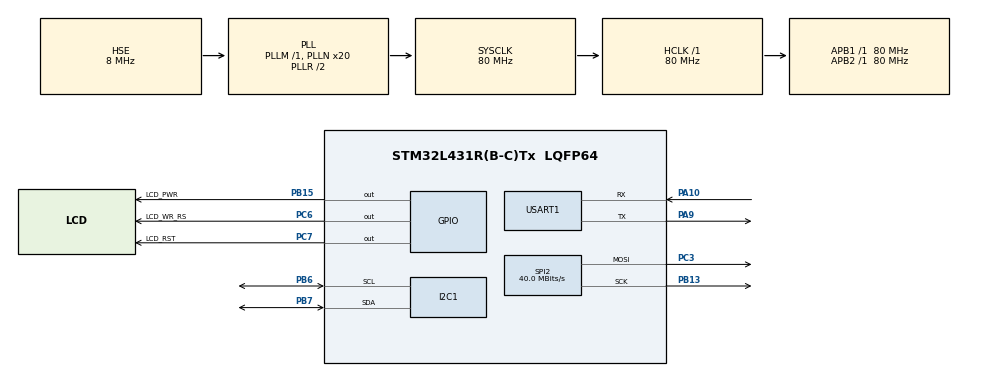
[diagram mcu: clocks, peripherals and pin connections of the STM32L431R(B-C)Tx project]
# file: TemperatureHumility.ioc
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Mcu.Family=STM32L4
Mcu.Name=STM32L431R(B-C)Tx
Mcu.Package=LQFP64
NVIC.PriorityGroup=NVIC_PRIORITYGROUP_4
PA10.Mode=Asynchronous
PA10.Signal=USART1_RX
PA9.Mode=Asynchronous
PA9.Signal=USART1_TX
PB13.Mode=TX_Only_Simplex_Unidirect_Master
PB13.Signal=SPI2_SCK
PB15.GPIO_Label=LCD_PWR
PB15.Signal=GPIO_Output
PB6.Mode=I2C
PB6.Signal=I2C1_SCL
PB7.Mode=I2C
PB7.Signal=I2C1_SDA
PC14-OSC32_IN\ (PC14).Mode=LSE-External-Oscillator
PC14-OSC32_IN\ (PC14).Signal=RCC_OSC32_IN
PC15-OSC32_OUT\ (PC15).Mode=LSE-External-Oscillator
PC15-OSC32_OUT\ (PC15).Signal=RCC_OSC32_OUT
PC3.Mode=TX_Only_Simplex_Unidirect_Master
PC3.Signal=SPI2_MOSI
PC6.GPIO_Label=LCD_WR_RS
PC6.Signal=GPIO_Output
PC7.GPIO_Label=LCD_RST
PC7.Signal=GPIO_Output
PH0-OSC_IN\ (PH0).Mode=HSE-External-Oscillator
PH0-OSC_IN\ (PH0).Signal=RCC_OSC_IN
PH1-OSC_OUT\ (PH1).Mode=HSE-External-Oscillator
PH1-OSC_OUT\ (PH1).Signal=RCC_OSC_OUT
ProjectManager.HeapSize=0x200
ProjectManager.StackSize=0x400
ProjectManager.TargetToolchain=SW4STM32
RCC.ADCFreq_Value=32000000
RCC.AHBFreq_Value=80000000
RCC.APB1Freq_Value=80000000
RCC.APB1TimFreq_Value=80000000
RCC.APB2Freq_Value=80000000
RCC.APB2TimFreq_Value=80000000
RCC.CortexFreq_Value=80000000
RCC.HCLKFreq_Value=80000000
RCC.HSE_VALUE=8000000
RCC.HSI48_VALUE=48000000
RCC.HSI_VALUE=16000000
RCC.MSI_VALUE=4000000
RCC.PLLN=20
RCC.PLLSourceVirtual=RCC_PLLSOURCE_HSE
RCC.SYSCLKFreq_VALUE=80000000
RCC.SYSCLKSource=RCC_SYSCLKSOURCE_PLLCLK
RCC.VCOOutputFreq_Value=160000000
SPI2.CLKPhase=SPI_PHASE_2EDGE
SPI2.CLKPolarity=SPI_POLARITY_HIGH
SPI2.CalculateBaudRate=40.0 MBits/s
SPI2.DataSize=SPI_DATASIZE_8BIT
SPI2.Direction=SPI_DIRECTION_2LINES
SPI2.Mode=SPI_MODE_MASTER
SPI2.VirtualType=VM_MASTER
USART1.VirtualMode-Asynchronous=VM_ASYNC
board=custom

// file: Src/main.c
/* USER CODE BEGIN Header */
/**
  ******************************************************************************
  * @file           : main.c
  * @brief          : Main program body
  ******************************************************************************
  * @attention
  *
  * <h2><center>&copy; Copyright (c) 2020 STMicroelectronics.
  * All rights reserved.</center></h2>
  *
  * This software component is licensed by ST under BSD 3-Clause license,
  * the "License"; You may not use this file except in compliance with the
  * License. You may obtain a copy of the License at:
  *                        opensource.org/licenses/BSD-3-Clause
  *
  ******************************************************************************
  */
/* USER CODE END Header */

#include "main.h"
#include "i2c.h"
#include "spi.h"
#include "usart.h"
#include "gpio.h"
#include "printfRedirection.h"
#include "sht30_i2c_drv.h"
#include <stdlib.h>
#include <lcd_spi2_drv.h>

void PrintFloat(float value)
{
    int tmp,tmp1,tmp2,tmp3,tmp4,tmp5,tmp6;
    tmp = (int)value;
    tmp1=(int)((value-tmp)*10)%10;
    tmp2=(int)((value-tmp)*100)%10;
    tmp3=(int)((value-tmp)*1000)%10;
    tmp4=(int)((value-tmp)*10000)%10;
    tmp5=(int)((value-tmp)*100000)%10;
    tmp6=(int)((value-tmp)*1000000)%10;
    printf("%d.%d%d%d%d%d%d",tmp,tmp1,tmp2,tmp3,tmp4,tmp5,tmp6);
}

void recurParse(int n, char** str, unsigned int* restSize) {
    if (n < 10) {
        if (*restSize > 1) {
            **str = n + '0';
            (*str)++;
            *restSize -= 1;
        }

    }
    else {
        recurParse(n / 10, str, restSize);
        if (*restSize > 1) {
            **str = n % 10 + '0';
            (*str)++;
            *restSize -= 1;
        }
    }
}
/*
*outBuffer: 输出字符串的缓冲区
*bufferSize: 输出字符串缓冲区的大小
*in: 要转换的浮点数
*decCount: 输出字符串保留的小数位数
*返回值: 写入到缓冲区中的字符个数（不包含\0）
*/
int float2String(char* outBuffer, unsigned int bufferSize, float in, unsigned int decCount) {
    int n;
    float dec;
    unsigned int restSize = bufferSize;
    if (restSize == 0) return 0;
    n = (int)in;
    dec = in - n;
    if (in < 0) {
        if (restSize > 1 && !(n == 0 && decCount == 0)) {
            *outBuffer++ = '-';
            --restSize;
        }
        n = -n;
    }
    if (dec < 0) {
        dec = -dec;
    }
    recurParse(n, &outBuffer, &restSize);
    if (decCount != 0) {
        if (restSize > 1) {
            *outBuffer++ = '.';
            --restSize;
        }
    }
    while (decCount) {
        dec *= 10;
        n = (int)dec;
        dec -= n;
        if (restSize > 1) {
            *outBuffer++ = n + '0';
            --restSize;
        }
        else {
            break;
        }
        decCount -= 1;
    }
    *outBuffer++ = NULL;
    return bufferSize - restSize;
}

void SystemClock_Config(void);

int main(void)
{
  /* USER CODE BEGIN 1 */
  uint8_t recv_dat[6] = {0};
  float temperature = 0.0;
  float humidity = 0.0;

    char strValue[8] = {0};

  /* USER CODE END 1 */

  /* MCU Configuration--------------------------------------------------------*/

  /* Reset of all peripherals, Initializes the Flash interface and the Systick. */
  HAL_Init();

  /* Configure the system clock */
  SystemClock_Config();

  /* Initialize all configured peripherals */
  MX_GPIO_Init();
  MX_I2C1_Init();
  MX_SPI2_Init();
  MX_USART1_UART_Init();
  /* USER CODE BEGIN 2 */
  LCD_Init();
  //LCD_Clear(GREEN);
  LCD_Clear(BLACK);

  SHT30_reset();
  if(SHT30_Init() == HAL_OK){
      printf("sht30 init ok.\n");
  }
  else{
      printf("sht30 init fail.\n");
  }

  /* USER CODE END 2 */

  /* Infinite loop */
  while (1)
  {
    HAL_Delay(1000);
    if(SHT30_Read_Dat(recv_dat) == HAL_OK){
        if(SHT30_Dat_To_Float(recv_dat, &temperature, &humidity) == 0) {
            printf("Temperature = ");PrintFloat(temperature);
            printf(", ");
            printf("Humidity = ");PrintFloat(humidity);
            printf("\n");
            LCD_ShowCharStr(0,120-32,180,"Temperature\:",BLACK,RED,24);
            float2String(strValue, sizeof(strValue)/sizeof(char), temperature, 2);
            LCD_ShowCharStr(160,120-32,60,strValue,BLACK,RED,24);

            LCD_ShowCharStr(0,120,180,"Humidity\:",BLACK,RED,24);
            float2String(strValue, sizeof(strValue)/sizeof(char), humidity, 2);
            LCD_ShowCharStr(160,120,60,strValue,BLACK,RED,24);
        }
        else{
            printf("crc check fail.\n");
        }
    }
    else{
        printf("read data from sht30 fail.\n");
    }

  }
}

void SystemClock_Config(void)
{
  RCC_OscInitTypeDef RCC_OscInitStruct = {0};
  RCC_ClkInitTypeDef RCC_ClkInitStruct = {0};
  RCC_PeriphCLKInitTypeDef PeriphClkInit = {0};

  /** Initializes the CPU, AHB and APB busses clocks
  */
  RCC_OscInitStruct.OscillatorType = RCC_OSCILLATORTYPE_HSE;
  RCC_OscInitStruct.HSEState = RCC_HSE_ON;
  RCC_OscInitStruct.PLL.PLLState = RCC_PLL_ON;
  RCC_OscInitStruct.PLL.PLLSource = RCC_PLLSOURCE_HSE;
  RCC_OscInitStruct.PLL.PLLM = 1;
  RCC_OscInitStruct.PLL.PLLN = 20;
  RCC_OscInitStruct.PLL.PLLP = RCC_PLLP_DIV7;
  RCC_OscInitStruct.PLL.PLLQ = RCC_PLLQ_DIV2;
  RCC_OscInitStruct.PLL.PLLR = RCC_PLLR_DIV2;
  if (HAL_RCC_OscConfig(&RCC_OscInitStruct) != HAL_OK)
  {
    Error_Handler();
  }
  /** Initializes the CPU, AHB and APB busses clocks
  */
  RCC_ClkInitStruct.ClockType = RCC_CLOCKTYPE_HCLK|RCC_CLOCKTYPE_SYSCLK
                              |RCC_CLOCKTYPE_PCLK1|RCC_CLOCKTYPE_PCLK2;
  RCC_ClkInitStruct.SYSCLKSource = RCC_SYSCLKSOURCE_PLLCLK;
  RCC_ClkInitStruct.AHBCLKDivider = RCC_SYSCLK_DIV1;
  RCC_ClkInitStruct.APB1CLKDivider = RCC_HCLK_DIV1;
  RCC_ClkInitStruct.APB2CLKDivider = RCC_HCLK_DIV1;

  if (HAL_RCC_ClockConfig(&RCC_ClkInitStruct, FLASH_LATENCY_4) != HAL_OK)
  {
    Error_Handler();
  }
  PeriphClkInit.PeriphClockSelection = RCC_PERIPHCLK_USART1|RCC_PERIPHCLK_I2C1;
  PeriphClkInit.Usart1ClockSelection = RCC_USART1CLKSOURCE_PCLK2;
  PeriphClkInit.I2c1ClockSelection = RCC_I2C1CLKSOURCE_PCLK1;
  if (HAL_RCCEx_PeriphCLKConfig(&PeriphClkInit) != HAL_OK)
  {
    Error_Handler();
  }
  /** Configure the main internal regulator output voltage
  */
  if (HAL_PWREx_ControlVoltageScaling(PWR_REGULATOR_VOLTAGE_SCALE1) != HAL_OK)
  {
    Error_Handler();
  }
}

void Error_Handler(void)
{
}

/************************ (C) COPYRIGHT STMicroelectronics *****END OF FILE****/
